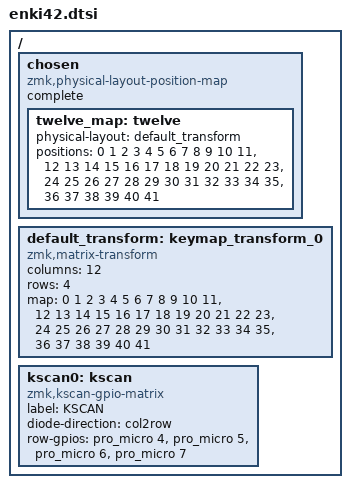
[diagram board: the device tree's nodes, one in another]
/*
 * Copyright (c) 2020 The ZMK Contributors
 *
 * SPDX-License-Identifier: MIT
 */

#include <physical_layouts.dtsi>

/ {

	chosen {
        /*compatible = "zmk,physical-layout";
        display-name = "Default Layout";
        transform = <&default_transform>;
        kscan = <&kscan0>;*/

		compatible = "zmk,physical-layout-position-map";

        complete;

        twelve_map: twelve {
            physical-layout = <&default_transform>;
            positions
                = < 0  1  2  3  4  5  6  7  8  9 10 11>
                , <12 13 14 15 16 17 18 19 20 21 22 23>
                , <24 25 26 27 28 29 30 31 32 33 34 35>
                , <         36 37 38 39 40 41         >;
        };
	};

	default_transform: keymap_transform_0 {
		compatible = "zmk,matrix-transform";
		columns = <12>;
		rows = <4>;

		// | SW1  | SW2  | SW3  | SW4  | SW5  | SW6  |   | SW6  | SW5  | SW4  | SW3  | SW2  | SW1  |
		// | SW7  | SW8  | SW9  | SW10 | SW11 | SW12 |   | SW12 | SW11 | SW10 | SW9  | SW8  | SW7  |
		// | SW13 | SW14 | SW15 | SW16 | SW17 | SW18 |   | SW18 | SW17 | SW16 | SW15 | SW14 | SW13 |
		//                      | SW19 | SW20 | SW21 |   | SW21 | SW20 | SW19 |
				map
					= < 0  1  2  3  4  5  6  7  8  9 10 11>
					, <12 13 14 15 16 17 18 19 20 21 22 23>
					, <24 25 26 27 28 29 30 31 32 33 34 35>
					, <         36 37 38 39 40 41         >;
	};

	kscan0: kscan {
		compatible = "zmk,kscan-gpio-matrix";
		label = "KSCAN";

		diode-direction = "col2row";
		row-gpios
			= <&pro_micro 4 (GPIO_ACTIVE_HIGH | GPIO_PULL_DOWN)>
			, <&pro_micro 5 (GPIO_ACTIVE_HIGH | GPIO_PULL_DOWN)>
			, <&pro_micro 6 (GPIO_ACTIVE_HIGH | GPIO_PULL_DOWN)>
			, <&pro_micro 7 (GPIO_ACTIVE_HIGH | GPIO_PULL_DOWN)>
			;
		
	};
};
